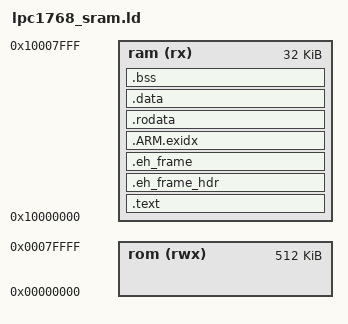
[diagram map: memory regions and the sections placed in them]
/*
* LPC1768のSRAM上でプログラムを動かすための最低限度のLDファイル。
* すべての資源をSRAM上に配置する。Sourcery G++ 2010q1-188の
* Generic-m-hosted.ldを修正して使用。
*/

OUTPUT_FORMAT ("elf32-littlearm", "elf32-bigarm", "elf32-littlearm")
ENTRY(_start)
SEARCH_DIR(.)

MEMORY
{
  rom (rwx) : ORIGIN = 0x00000000, LENGTH = 512K
  ram (rx) :  ORIGIN = 0x10000000, LENGTH = 32K
}


/* Provide fall-back values */
PROVIDE( __data_start = 0x0 );				/* 以下の3シンボルはダミーだが、0でなければならない */
PROVIDE( __idata_start = 0x0 );
PROVIDE( __idata_end = 0x0 );
PROVIDE( _vector_start = 0x0 );				/* SRAM版とROM版でコードを共有するためのダミー*/
PROVIDE( _vector_end = 0x0 );


PROVIDE(hardware_init_hook = 0);
PROVIDE(software_init_hook = 0);
PROVIDE(software_term_hook = 0);
STARTUP(start.o)


SECTIONS
{
  .text :
  {
  	_vector_start_lma = .;
	*( .vector )		/* RAM領域の先頭に割り当てているのは、 256byte境界を守るため */
    *(.text .text.* .gnu.linkonce.t.*)
    *(.plt)
    *(.gnu.warning)
    *(.glue_7t) *(.glue_7) *(.vfp11_veneer)

    *(.ARM.extab* .gnu.linkonce.armextab.*)
    *(.gcc_except_table)
  } >ram
  
  .eh_frame_hdr : ALIGN (4)
  {
    KEEP (*(.eh_frame_hdr))
  } >ram
  
  .eh_frame : ALIGN (4)
  {
    KEEP (*(.eh_frame))
  } >ram
  
  /* .ARM.exidx is sorted, so has to go in its own output section.  */
  PROVIDE_HIDDEN (__exidx_start = .);
  .ARM.exidx :
  {
    *(.ARM.exidx* .gnu.linkonce.armexidx.*)
  } >ram

  PROVIDE_HIDDEN (__exidx_end = .);
  .rodata : ALIGN (4)
  {
    *(.rodata .rodata.* .gnu.linkonce.r.*)

    . = ALIGN(4);
    KEEP(*(.init))

    . = ALIGN(4);
    __preinit_array_start = .;
    KEEP (*(.preinit_array))
    __preinit_array_end = .;

    . = ALIGN(4);
    __init_array_start = .;
    KEEP (*(SORT(.init_array.*)))
    KEEP (*(.init_array))
    __init_array_end = .;

    . = ALIGN(4);
    KEEP(*(.fini))

    . = ALIGN(4);
    __fini_array_start = .;
    KEEP (*(.fini_array))
    KEEP (*(SORT(.fini_array.*)))
    __fini_array_end = .;

    . = ALIGN(0x4);
    KEEP (*crtbegin.o(.ctors))
    KEEP (*(EXCLUDE_FILE (*crtend.o) .ctors))
    KEEP (*(SORT(.ctors.*)))
    KEEP (*crtend.o(.ctors))

    . = ALIGN(0x4);
    KEEP (*crtbegin.o(.dtors))
    KEEP (*(EXCLUDE_FILE (*crtend.o) .dtors))
    KEEP (*(SORT(.dtors.*)))
    KEEP (*crtend.o(.dtors))

    . = ALIGN (8);
    _etext = .;
  } >ram

  .data : ALIGN (8)
  {
    KEEP(*(.jcr))
    *(.got.plt) *(.got)
    *(.shdata)
    *(.data .data.* .gnu.linkonce.d.*)
    . = ALIGN (8);
    *(.ram)
    _edata = .;
  } >ram
  
  .bss :
  {
    __bss_start = .;
    *(.shbss)
    *(.bss .bss.* .gnu.linkonce.b.*)
    *(COMMON)
    . = ALIGN (8);
    *(.ram.b .bss.ram)
    _end = .;
    __end = .;
    __bss_end = .;
  } >ram

  .stab 0 (NOLOAD) : { *(.stab) }
  .stabstr 0 (NOLOAD) : { *(.stabstr) }
  /* DWARF debug sections.
   * Symbols in the DWARF debugging sections are relative to
   * the beginning of the section so we begin them at 0.
   */
  /* DWARF 1 */
  .debug          0 : { *(.debug) }
  .line           0 : { *(.line) }
  /* GNU DWARF 1 extensions */
  .debug_srcinfo  0 : { *(.debug_srcinfo) }
  .debug_sfnames  0 : { *(.debug_sfnames) }
  /* DWARF 1.1 and DWARF 2 */
  .debug_aranges  0 : { *(.debug_aranges) }
  .debug_pubnames 0 : { *(.debug_pubnames) }
  /* DWARF 2 */
  .debug_info     0 : { *(.debug_info .gnu.linkonce.wi.*) }
  .debug_abbrev   0 : { *(.debug_abbrev) }
  .debug_line     0 : { *(.debug_line) }
  .debug_frame    0 : { *(.debug_frame) }
  .debug_str      0 : { *(.debug_str) }
  .debug_loc      0 : { *(.debug_loc) }
  .debug_macinfo  0 : { *(.debug_macinfo) }
  /* DWARF 2.1 */
  .debug_ranges   0 : { *(.debug_ranges) }
  /* SGI/MIPS DWARF 2 extensions */
  .debug_weaknames 0 : { *(.debug_weaknames) }
  .debug_funcnames 0 : { *(.debug_funcnames) }
  .debug_typenames 0 : { *(.debug_typenames) }
  .debug_varnames  0 : { *(.debug_varnames) }

  .note.gnu.arm.ident 0 : { KEEP (*(.note.gnu.arm.ident)) }
  .ARM.attributes 0 : { KEEP (*(.ARM.attributes)) }
  /DISCARD/ : { *(.note.GNU-stack) }
}
